# UART3 register map
Registers from a debugger description file.
Registers are 32-bit, access not given, no defined reset value unless marked. A register's access mark holds for its fields unless they carry their own. Addresses are absolute; registers are grouped by the start of their names; lines under a group give offsets from that group; [hi:lo] are bit positions; {n}, {i} and the like mark numbered series; 'fields as' and 'values as' point back to an identical list; <NAME> marks a mode.

## UART3
0x40062000 UART3/THR
  [7:0] THR
0x40062000 UART3/DLL
  [7:0] DLL
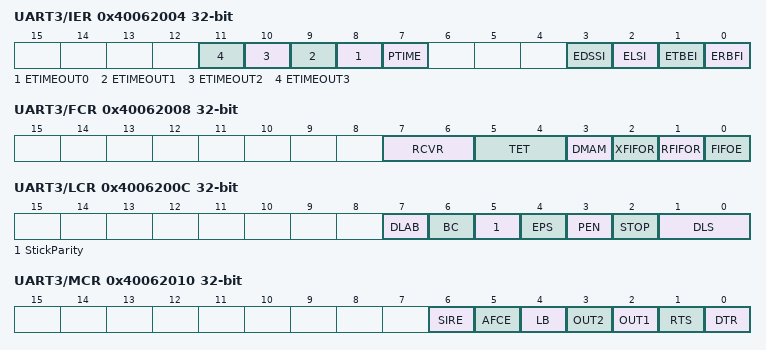
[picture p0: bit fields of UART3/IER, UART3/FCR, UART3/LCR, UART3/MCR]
0x40062004 UART3/IER
  [n+8] ETIMEOUT{n} (n=0..3), [7] PTIME, [3] EDSSI, [2] ELSI, [1] ETBEI, [0] ERBFI
0x40062004 UART3/DLH
  [7:0] DLH
0x40062008 UART3/FCR
  [7:6] RCVR, [5:4] TET, [3] DMAM, [2] XFIFOR, [1] RFIFOR, [0] FIFOE
0x4006200C UART3/LCR
  [7] DLAB, [6] BC, [5] StickParity, [4] EPS, [3] PEN, [2] STOP, [1:0] DLS
0x40062010 UART3/MCR
  [6] SIRE, [5] AFCE, [4] LB, [3] OUT2, [2] OUT1, [1] RTS, [0] DTR
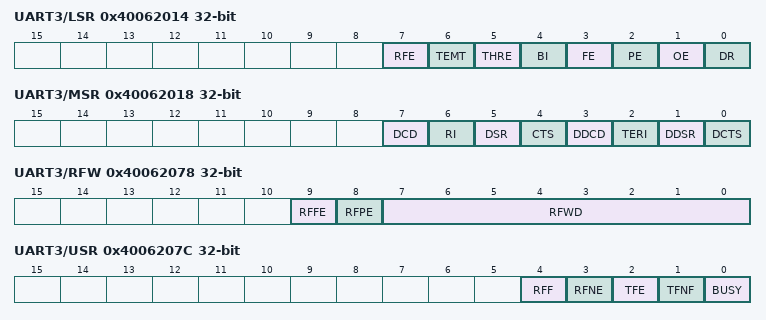
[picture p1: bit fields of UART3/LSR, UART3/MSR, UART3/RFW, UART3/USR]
0x40062014 UART3/LSR ro
  [7] RFE, [6] TEMT, [5] THRE, [4] BI, [3] FE, [2] PE, [1] OE, [0] DR
0x40062018 UART3/MSR ro
  [7] DCD, [6] RI, [5] DSR, [4] CTS, [3] DDCD, [2] TERI, [1] DDSR, [0] DCTS
0x4006201C UART3/SCR
  [7:0] SCR
0x40062030 UART3/STHR
  [7:0] STHR
0x40062070 UART3/FAR
  [0] FAR
0x40062074 UART3/TFR ro
  [7:0] TFR
0x40062078 UART3/RFW
  [9] RFFE, [8] RFPE, [7:0] RFWD
0x4006207C UART3/USR ro
  [4] RFF, [3] RFNE, [2] TFE, [1] TFNF, [0] BUSY
0x40062080 UART3/TFL ro
  [4:0] TFL
0x40062084 UART3/RFL ro
  [4:0] RFL
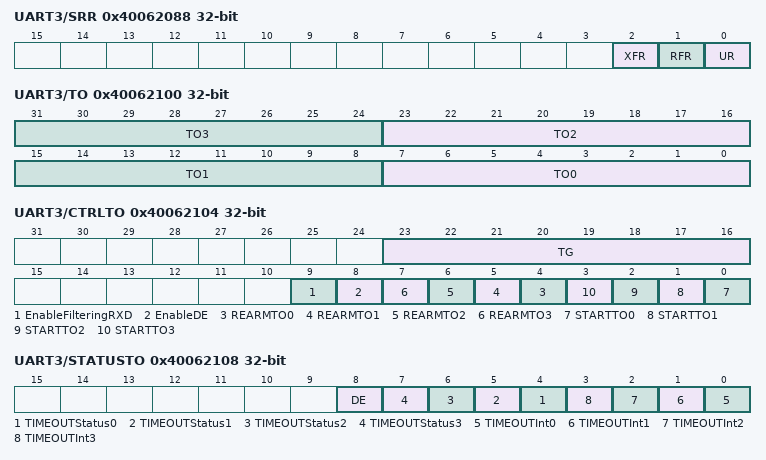
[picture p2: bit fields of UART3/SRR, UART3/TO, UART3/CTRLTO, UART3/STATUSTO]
0x40062088 UART3/SRR
  [2] XFR, [1] RFR, [0] UR
0x4006208C UART3/SRTS
  [0] SRTS
0x40062090 UART3/SBCR
  [0] SBCR
0x40062098 UART3/SFE
  [0] SFE
0x4006209C UART3/SRT
  [1:0] SRCVR
0x400620A0 UART3/STET
  [1:0] STET
0x400620A4 UART3/HTX
  [0] HTX
0x400620F8 UART3/UCV ro
  [31:0] Version
0x400620FC UART3/CTR ro
  [31:0] ID
0x40062100 UART3/TO
  [8n+7:8n] TO{n} (n=0..3)
0x40062104 UART3/CTRLTO
  [23:16] TG, [9] EnableFilteringRXD, [8] EnableDE, [n+4] REARMTO{n} (n=0..3), [n] STARTTO{n} (n=0..3)
0x40062108 UART3/STATUSTO
  [8] DE, [n+4] TIMEOUTStatus{n} (n=0..3), [n] TIMEOUTInt{n} (n=0..3)
